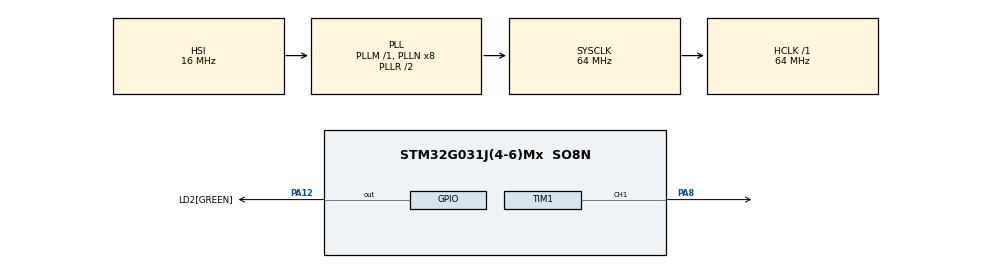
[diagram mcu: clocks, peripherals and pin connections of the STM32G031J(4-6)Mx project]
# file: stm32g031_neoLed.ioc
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Dma.Request0=TIM1_CH1
Dma.TIM1_CH1.0.Direction=DMA_MEMORY_TO_PERIPH
Dma.TIM1_CH1.0.EventEnable=DISABLE
Dma.TIM1_CH1.0.Instance=DMA1_Channel1
Dma.TIM1_CH1.0.MemDataAlignment=DMA_MDATAALIGN_HALFWORD
Dma.TIM1_CH1.0.MemInc=DMA_MINC_ENABLE
Dma.TIM1_CH1.0.Mode=DMA_NORMAL
Dma.TIM1_CH1.0.PeriphDataAlignment=DMA_PDATAALIGN_HALFWORD
Dma.TIM1_CH1.0.PeriphInc=DMA_PINC_DISABLE
Dma.TIM1_CH1.0.Polarity=HAL_DMAMUX_REQ_GEN_RISING
Dma.TIM1_CH1.0.Priority=DMA_PRIORITY_LOW
Dma.TIM1_CH1.0.RequestNumber=1
Dma.TIM1_CH1.0.SignalID=NONE
Dma.TIM1_CH1.0.SyncEnable=DISABLE
Dma.TIM1_CH1.0.SyncPolarity=HAL_DMAMUX_SYNC_NO_EVENT
Dma.TIM1_CH1.0.SyncRequestNumber=1
Dma.TIM1_CH1.0.SyncSignalID=NONE
Mcu.Family=STM32G0
Mcu.Name=STM32G031J(4-6)Mx
Mcu.Package=SO8N
NVIC.DMA1_Channel1_IRQn=true\:0\:0\:false\:false\:true\:false\:true\:true
PA12\ [PA10].GPIO_Label=LD2[GREEN]
PA12\ [PA10].Signal=GPIO_Output
PA13.Mode=Serial_Wire
PA13.Signal=SYS_SWDIO
PA14-BOOT0.Mode=Serial_Wire
PA14-BOOT0.Signal=SYS_SWCLK
PA14-BOOT0__PA15__PB5__PB6.StandardMode=true
PA8.PinState=GPIO_PIN_RESET
PA8.Signal=S_TIM1_CH1
PB0__PB1__PA8__PA11\ [PA9].StandardMode=true
PC14-OSC32_IN\ (PC14)__PB7__PB8__PB9.StandardMode=true
PF2\ -\ NRST__PA0__PA1__PA2.StandardMode=true
ProjectManager.HeapSize=0x200
ProjectManager.StackSize=0x400
ProjectManager.TargetToolchain=STM32CubeIDE
RCC.ADCFreq_Value=64000000
RCC.AHBFreq_Value=64000000
RCC.CortexFreq_Value=64000000
RCC.EXTERNAL_CLOCK_VALUE=12288000
RCC.HCLKFreq_Value=64000000
RCC.HSE_VALUE=8000000
RCC.HSI_VALUE=16000000
RCC.LSE_VALUE=32768
RCC.SYSCLKFreq_VALUE=64000000
RCC.SYSCLKSource=RCC_SYSCLKSOURCE_PLLCLK
RCC.VCOOutputFreq_Value=128000000
SH.S_TIM1_CH1.0=TIM1_CH1,PWM Generation1 CH1
TIM1.Channel-PWM\ Generation1\ CH1=TIM_CHANNEL_1
TIM1.OCIdleState_1=TIM_OCIDLESTATE_RESET
TIM1.Period=80 - 1
TIM1.Prescaler=1 - 1
TIM1.Pulse-PWM\ Generation1\ CH1=26
VP_TIM1_VS_ClockSourceINT.Mode=Internal
board=STM32G0316-DISCO

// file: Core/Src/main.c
/* USER CODE BEGIN Header */
/**
  ******************************************************************************
  * @file           : main.c
  * @brief          : Main program body
  ******************************************************************************
  * @attention
  *
  * Copyright (c) 2023 STMicroelectronics.
  * All rights reserved.
  *
  * This software is licensed under terms that can be found in the LICENSE file
  * in the root directory of this software component.
  * If no LICENSE file comes with this software, it is provided AS-IS.
  *
  ******************************************************************************
  */
/* USER CODE END Header */
#include "main.h"
#include "dma.h"
#include "tim.h"
#include "gpio.h"

/* USER CODE BEGIN Includes */

#include "led.h"
/* USER CODE END Includes */

void SystemClock_Config(void);

/* USER CODE BEGIN 0 */

void HAL_TIM_PWM_PulseFinishedCallback(TIM_HandleTypeDef *htim)
{
	if(htim->Instance == htim1.Instance)
	{
		HAL_TIM_PWM_Stop_DMA(&htim1, TIM_CHANNEL_1);
		led_state_inst.pwm_tx_done = true;
	}
}

/* USER CODE END 0 */

int main(void)
{

  /* MCU Configuration--------------------------------------------------------*/

  /* Reset of all peripherals, Initializes the Flash interface and the Systick. */
  HAL_Init();

  /* Configure the system clock */
  SystemClock_Config();

  /* Initialize all configured peripherals */
  MX_GPIO_Init();
  MX_DMA_Init();
  MX_TIM1_Init();
  /* USER CODE BEGIN 2 */
  int length = HW_LED_LENGTH_MAX;
  ledInit(length, 100);

  drawCarrot(1);
  /* USER CODE END 2 */

  /* Infinite loop */
  while (1)
  {

  }
}

void SystemClock_Config(void)
{
  RCC_OscInitTypeDef RCC_OscInitStruct = {0};
  RCC_ClkInitTypeDef RCC_ClkInitStruct = {0};

  /** Configure the main internal regulator output voltage
  */
  HAL_PWREx_ControlVoltageScaling(PWR_REGULATOR_VOLTAGE_SCALE1);

  /** Initializes the RCC Oscillators according to the specified parameters
  * in the RCC_OscInitTypeDef structure.
  */
  RCC_OscInitStruct.OscillatorType = RCC_OSCILLATORTYPE_HSI;
  RCC_OscInitStruct.HSIState = RCC_HSI_ON;
  RCC_OscInitStruct.HSIDiv = RCC_HSI_DIV1;
  RCC_OscInitStruct.HSICalibrationValue = RCC_HSICALIBRATION_DEFAULT;
  RCC_OscInitStruct.PLL.PLLState = RCC_PLL_ON;
  RCC_OscInitStruct.PLL.PLLSource = RCC_PLLSOURCE_HSI;
  RCC_OscInitStruct.PLL.PLLM = RCC_PLLM_DIV1;
  RCC_OscInitStruct.PLL.PLLN = 8;
  RCC_OscInitStruct.PLL.PLLP = RCC_PLLP_DIV2;
  RCC_OscInitStruct.PLL.PLLQ = RCC_PLLQ_DIV2;
  RCC_OscInitStruct.PLL.PLLR = RCC_PLLR_DIV2;
  if (HAL_RCC_OscConfig(&RCC_OscInitStruct) != HAL_OK)
  {
    Error_Handler();
  }

  /** Initializes the CPU, AHB and APB buses clocks
  */
  RCC_ClkInitStruct.ClockType = RCC_CLOCKTYPE_HCLK|RCC_CLOCKTYPE_SYSCLK
                              |RCC_CLOCKTYPE_PCLK1;
  RCC_ClkInitStruct.SYSCLKSource = RCC_SYSCLKSOURCE_PLLCLK;
  RCC_ClkInitStruct.AHBCLKDivider = RCC_SYSCLK_DIV1;
  RCC_ClkInitStruct.APB1CLKDivider = RCC_HCLK_DIV1;

  if (HAL_RCC_ClockConfig(&RCC_ClkInitStruct, FLASH_LATENCY_2) != HAL_OK)
  {
    Error_Handler();
  }
}

void Error_Handler(void)
{
  __disable_irq();
  while (1)
  {
  }
}
